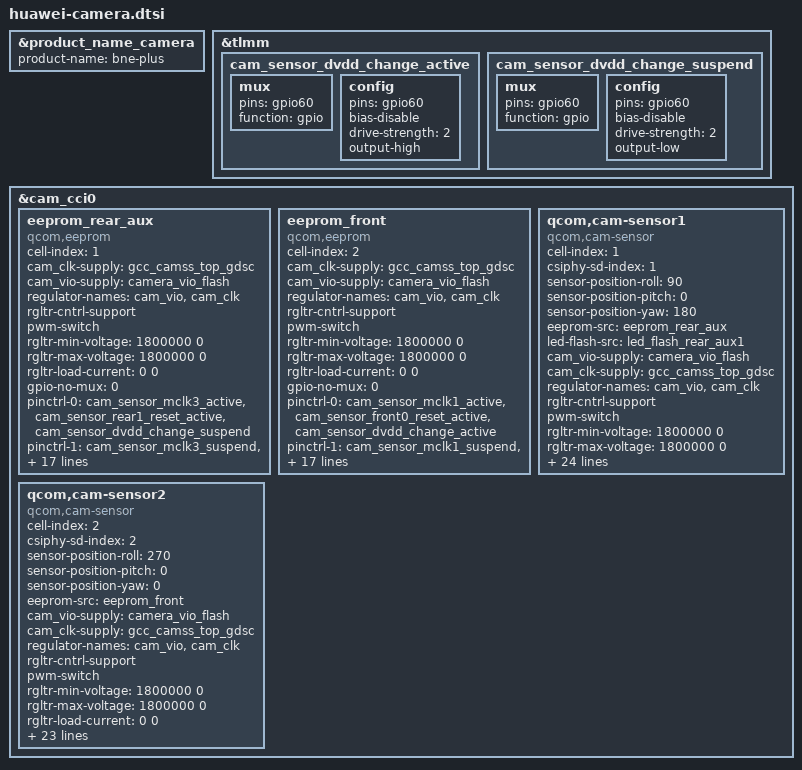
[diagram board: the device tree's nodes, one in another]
#include "../../../camera/khaje-camera-sensor-bne-vn1b_8565.dtsi"

&product_name_camera {
	product-name = "bne-plus";
};

&tlmm {
	cam_sensor_dvdd_change_active {
		/* dvdd_change */
		mux {
			pins = "gpio60";
			function = "gpio";
		};

		config {
			pins = "gpio60";
			bias-disable; /* No PULL */
			drive-strength = <2>; /* 2 MA */
			output-high;
		};
	};

	cam_sensor_dvdd_change_suspend {
		/* dvdd_change */
		mux {
			pins = "gpio60";
			function = "gpio";
		};

		config {
			pins = "gpio60";
			bias-disable; /* No PULL */
			drive-strength = <2>; /* 2 MA */
			output-low;
		};
	};
};

&cam_cci0 {
	// Rear Aux wide&depth eeprom
	eeprom_rear_aux {
		cell-index = <1>;
		compatible = "qcom,eeprom";
		cam_clk-supply = <&gcc_camss_top_gdsc>;
		cam_vio-supply = <&camera_vio_flash>;
		regulator-names =  "cam_vio", "cam_clk";
		rgltr-cntrl-support;
		pwm-switch;
		rgltr-min-voltage = <1800000 0>;
		rgltr-max-voltage = <1800000 0>;
		rgltr-load-current = <0 0>;
		gpio-no-mux = <0>;
		pinctrl-names = "cam_default", "cam_suspend";
		pinctrl-0 = <&cam_sensor_mclk3_active
			&cam_sensor_rear1_reset_active
			&cam_sensor_dvdd_change_suspend>;
		pinctrl-1 = <&cam_sensor_mclk3_suspend
			&cam_sensor_rear1_reset_suspend
			&cam_sensor_dvdd_change_suspend>;
		gpios = <&tlmm 28 0>,
			<&tlmm 24 0>,
			<&pm6125_gpios 2 0>,
			<&tlmm 103 0>,
			<&tlmm 60 0>;
		gpio-reset = <1>;
		gpio-custom-vana = <2>;
		gpio-custom1 = <3>;
		gpio-custom2 = <4>;
		gpio-req-tbl-num = <0 1 2 3 4>;
		gpio-req-tbl-flags = <1 0 0 0 0>;
		gpio-req-tbl-label = "CAMIF_MCLK1",
			"CAM_RESET1",
			"CAM_AVDD1",
			"CAM_DVDD1",
			"CAM_DVDD_CHANGE1";
		sensor-mode = <0>;
		cci-master = <1>;
		status = "ok";
		clocks = <&gcc GCC_CAMSS_MCLK3_CLK>;
		clock-names = "cam_clk";
		clock-cntl-level = "turbo";
		clock-rates = <19200000>;
	};

	// Front eepom
	eeprom_front {
		cell-index = <2>;
		compatible = "qcom,eeprom";
		cam_clk-supply = <&gcc_camss_top_gdsc>;
		cam_vio-supply = <&camera_vio_flash>;
		regulator-names =  "cam_vio", "cam_clk";
		rgltr-cntrl-support;
		pwm-switch;
		rgltr-min-voltage = <1800000 0>;
		rgltr-max-voltage = <1800000 0>;
		rgltr-load-current = <0 0>;
		gpio-no-mux = <0>;
		pinctrl-names = "cam_default", "cam_suspend";
		pinctrl-0 = <&cam_sensor_mclk1_active
			&cam_sensor_front0_reset_active
			&cam_sensor_dvdd_change_active>;
		pinctrl-1 = <&cam_sensor_mclk1_suspend
			&cam_sensor_front0_reset_suspend
			&cam_sensor_dvdd_change_suspend>;
		gpios = <&tlmm 21 0>,
			<&tlmm 19 0>,
			<&pm6125_gpios 2 0>,
			<&tlmm 103 0>,
			<&tlmm 60 0>;
		gpio-reset = <1>;
		gpio-custom-vana = <2>;
		gpio-custom1 = <3>;
		gpio-custom2 = <4>;
		gpio-req-tbl-num = <0 1 2 3 4>;
		gpio-req-tbl-flags = <1 0 0 0 0>;
		gpio-req-tbl-label = "CAMIF_MCLK2",
			"CAM_RESET2",
			"CAM_AVDD2",
			"CAM_DVDD2",
			"CAM_DVDD_CHANGE2";
		sensor-mode = <0>;
		cci-master = <0>;
		status = "ok";
		clocks = <&gcc GCC_CAMSS_MCLK1_CLK>;
		clock-names = "cam_clk";
		clock-cntl-level = "turbo";
		clock-rates = <19200000>;
	};

	// Rear Aux wide&depth
	qcom,cam-sensor1 {
		cell-index = <1>;
		compatible = "qcom,cam-sensor";
		csiphy-sd-index = <1>;
		sensor-position-roll = <90>;
		sensor-position-pitch = <0>;
		sensor-position-yaw = <180>;
		eeprom-src = <&eeprom_rear_aux>;
		led-flash-src = <&led_flash_rear_aux1>;
		cam_vio-supply = <&camera_vio_flash>;
		cam_clk-supply = <&gcc_camss_top_gdsc>;
		regulator-names = "cam_vio", "cam_clk";
		rgltr-cntrl-support;
		pwm-switch;
		rgltr-min-voltage = <1800000 0>;
		rgltr-max-voltage = <1800000 0>;
		rgltr-load-current = <0 0>;
		gpio-no-mux = <0>;
		pinctrl-names = "cam_default", "cam_suspend";
		pinctrl-0 = <&cam_sensor_mclk3_active
			&cam_sensor_rear1_reset_active
			&cam_sensor_dvdd_change_suspend>;
		pinctrl-1 = <&cam_sensor_mclk3_suspend
			&cam_sensor_rear1_reset_suspend
			&cam_sensor_dvdd_change_suspend>;
		gpios = <&tlmm 28 0>,
			<&tlmm 24 0>,
			<&pm6125_gpios 2 0>,
			<&tlmm 103 0>,
			<&tlmm 60 0>;
		gpio-reset = <1>;
		gpio-custom-vana = <2>;
		gpio-custom1 = <3>;
		gpio-custom2 = <4>;
		gpio-req-tbl-num = <0 1 2 3 4>;
		gpio-req-tbl-flags = <1 0 0 0 0>;
		gpio-req-tbl-label = "CAMIF_MCLK1",
			"CAM_RESET1",
			"CAM_AVDD1",
			"CAM_DVDD1",
			"CAM_DVDD_CHANGE1";
		sensor-mode = <0>;
		cci-master = <1>;
		status = "ok";
		clocks = <&gcc GCC_CAMSS_MCLK3_CLK>;
		clock-names = "cam_clk";
		clock-cntl-level = "turbo";
		clock-rates = <19200000>;
		ic_position = <2>; /* CAMERA_POSITION_REAR_SECOND */
	};

	// Front
	qcom,cam-sensor2 {
		cell-index = <2>;
		compatible = "qcom,cam-sensor";
		csiphy-sd-index = <2>;
		sensor-position-roll = <270>;
		sensor-position-pitch = <0>;
		sensor-position-yaw = <0>;
		eeprom-src = <&eeprom_front>;
		cam_vio-supply = <&camera_vio_flash>;
		cam_clk-supply = <&gcc_camss_top_gdsc>;
		regulator-names =  "cam_vio", "cam_clk";
		rgltr-cntrl-support;
		pwm-switch;
		rgltr-min-voltage = <1800000 0>;
		rgltr-max-voltage = <1800000 0>;
		rgltr-load-current = <0 0>;
		gpio-no-mux = <0>;
		pinctrl-names = "cam_default", "cam_suspend";
		pinctrl-0 = <&cam_sensor_mclk1_active
			&cam_sensor_front0_reset_active
			&cam_sensor_dvdd_change_active>;
		pinctrl-1 = <&cam_sensor_mclk1_suspend
			&cam_sensor_front0_reset_suspend
			&cam_sensor_dvdd_change_suspend>;
		gpios = <&tlmm 21 0>,
			<&tlmm 19 0>,
			<&pm6125_gpios 2 0>,
			<&tlmm 103 0>,
			<&tlmm 60 0>;
		gpio-reset = <1>;
		gpio-custom-vana = <2>;
		gpio-custom1 = <3>;
		gpio-custom2 = <4>;
		gpio-req-tbl-num = <0 1 2 3 4>;
		gpio-req-tbl-flags = <1 0 0 0 0>;
		gpio-req-tbl-label = "CAMIF_MCLK2",
			"CAM_RESET2",
			"CAM_AVDD2",
			"CAM_DVDD2",
			"CAM_DVDD_CHANGE2";
		sensor-mode = <0>;
		cci-master = <0>;
		status = "ok";
		clocks = <&gcc GCC_CAMSS_MCLK1_CLK>;
		clock-names = "cam_clk";
		clock-cntl-level = "turbo";
		clock-rates = <19200000>;
		ic_position = <1>; /* CAMERA_POSITION_FORE */
	};
};

